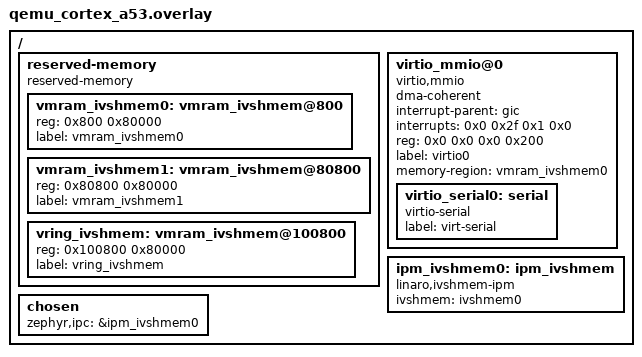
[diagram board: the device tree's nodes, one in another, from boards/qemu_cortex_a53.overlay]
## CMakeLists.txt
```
# SPDX-License-Identifier: Apache-2.0

cmake_minimum_required(VERSION 3.13.1)

# list(APPEND QEMU_EXTRA_FLAGS -S)
# list(APPEND QEMU_EXTRA_FLAGS -s)

find_package(Zephyr REQUIRED HINTS $ENV{ZEPHYR_BASE})
project(hello_world)
zephyr_compile_definitions(METAL_MAX_DEVICE_REGIONS=2)

target_sources(app PRIVATE src/main.c src/virtio_mmio_ivshmem.c)
```

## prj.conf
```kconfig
CONFIG_VIRTIO=y
CONFIG_VIRTIO_MMIO=y
CONFIG_VIRTIO_MMIO_USE_IVSHMEM=y
CONFIG_COMPILER_OPT=" -DHVL_VIRTIO"
CONFIG_VIRTIO_SERIAL=y
CONFIG_UART_INTERRUPT_DRIVEN=n

CONFIG_BOOT_BANNER=n
CONFIG_EARLY_CONSOLE=n
CONFIG_CONSOLE=n

CONFIG_OPENAMP=y
CONFIG_LIBMETAL=y
# CONFIG_HEAP_MEM_POOL_SIZE=131072
CONFIG_IPM=y
```

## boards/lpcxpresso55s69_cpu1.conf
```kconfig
CONFIG_IPM_MCUX=y
```

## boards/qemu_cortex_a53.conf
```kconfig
# Copyright (c) 2023 Linaro
# SPDX-License-Identifier: Apache-2.0

CONFIG_PCIE_CONTROLLER=y
CONFIG_PCIE_ECAM=y

# Hungry PCI requires at least 256M of virtual space
CONFIG_KERNEL_VM_SIZE=0x80000000

# Hungry PCI requires phys addresses with more than 32 bits
CONFIG_ARM64_VA_BITS_40=y
CONFIG_ARM64_PA_BITS_40=y

# MSI support requires ITS
CONFIG_GIC_V3_ITS=y

# ITS, in turn, requires dynamic memory (9x64 + alignment constrains)
# Additionally, our test also uses malloc
CONFIG_HEAP_MEM_POOL_SIZE=1048576
CONFIG_IPM_IVSHMEM_EVENT_LOOP_PRIO=0

CONFIG_PCIE=y
# required by doorbell
CONFIG_PCIE_MSI=y
CONFIG_PCIE_MSI_X=y
CONFIG_PCIE_MSI_MULTI_VECTOR=y
CONFIG_POLL=y

CONFIG_VIRTUALIZATION=y
CONFIG_IVSHMEM=y
CONFIG_IVSHMEM_DOORBELL=y
```

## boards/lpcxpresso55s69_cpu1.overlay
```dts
/*
 * Copyright (c) 2019 Linaro Limited
 *
 * SPDX-License-Identifier: Apache-2.0
 */

 / {
	chosen {
		zephyr,ipc = &mailbox0;
	};

	/* This is a duplication of sram4, workaround */
	sram4duplicate: memory@20040000 {
		compatible = "mmio-sram";
		reg = <0x20040000 DT_SIZE_K(16)>;
	};

	virtio_mmio@20040000 {
		dma-coherent;
		interrupt-parent = < &nvic >;
		/* use the same interrupt from mailbox peripheral*/
		interrupts = <31 0>;;
		reg = < 20040000 0x200 >;
		compatible = "virtio,mmio";
		status = "okay";
		label = "virtio0";
		memory-region = < &sram4duplicate >;
		virtio_serial0: serial {
			label = "virt-serial";
			compatible = "virtio-serial";
		};
	};
};
```

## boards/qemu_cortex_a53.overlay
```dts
/*
 * Copyright 2023 Linaro.
 *
 * SPDX-License-Identifier: Apache-2.0
 */
#include "pcie_ivshmem.dtsi"

/{
	reserved-memory {
		compatible = "reserved-memory";
		#address-cells = <1>;
		#size-cells = <1>;
		status = "okay";
		ranges;

		vmram_ivshmem0: vmram_ivshmem@800 {
			status = "okay";
			reg = < 0x800 0x80000 >;
			device_type = "memory";
			label = "vmram_ivshmem0";
		};

		vmram_ivshmem1: vmram_ivshmem@80800 {
			status = "okay";
			reg = < 0x80800 0x80000 >;
			device_type = "memory";
			label = "vmram_ivshmem1";
		};

		/* reserve this area for the vrings */
		vring_ivshmem: vmram_ivshmem@100800 {
			status = "okay";
			reg = < 0x100800 0x80000 >;
			device_type = "memory";
			label = "vring_ivshmem";
		};
	};

	virtio_mmio@0 {
		dma-coherent;
		interrupt-parent = < &gic >;
		interrupts = < 0x0 0x2f 0x1 0x0 >;
		reg = < 0x0 0x0 0x0 0x200 >;
		compatible = "virtio,mmio";
		status = "okay";
		label = "virtio0";
		memory-region = < &vmram_ivshmem0 >;
		virtio_serial0: serial {
			label = "virt-serial";
			compatible = "virtio-serial";
		};
	};

	ipm_ivshmem0: ipm_ivshmem {
		compatible = "linaro,ivshmem-ipm";
		ivshmem = <&ivshmem0>;
		status = "okay";
	};

	chosen {
		zephyr,ipc = &ipm_ivshmem0;
	};
};
```

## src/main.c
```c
/*
 * Copyright (c) 2012-2014 Wind River Systems, Inc.
 *
 * SPDX-License-Identifier: Apache-2.0
 */

#include <zephyr/kernel.h>
#include <zephyr/sys/printk.h>
#include <zephyr/init.h>
#include <zephyr/drivers/uart.h>

const struct device *virtio_serial = DEVICE_DT_GET(DT_NODELABEL(virtio_serial0));

/* override the printk output char with our virtio_serial driver: */
int arch_printk_char_out(int c)
{
	if(!device_is_ready(virtio_serial))
		return 0;

	uart_poll_out(virtio_serial, c);
	k_sleep(K_USEC(200));
	return 0;
}

void main(void)
{
	while(1){
		printk("[%d]: Hello World I'm %s sending data over Virtio-MMIO Serial Port\n",
			k_uptime_get_32(),
			CONFIG_BOARD);
	}
}
```

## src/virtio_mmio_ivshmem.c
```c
/*
 * Copyright (c) 2023, Linaro Limited
 *
 * SPDX-License-Identifier: Apache-2.0
 */
#include <stdio.h>
#include <string.h>

#include <zephyr/device.h>
#include <zephyr/drivers/virtualization/ivshmem.h>
#include <zephyr/drivers/ipm.h>
#include <zephyr/sys/printk.h>
#include <zephyr/kernel.h>
#include <zephyr/init.h>

#include <openamp/virtio_mmio.h>

static const struct device *ivshmem_dev =
		DEVICE_DT_GET(DT_NODELABEL(ivshmem0));

static const struct device *ipm_dev =
		DEVICE_DT_GET(DT_CHOSEN(zephyr_ipc));

static void ipm_platform_callback(const struct device *ipmdev,
						void *user_data,
			       		uint32_t id,
						volatile void *data)
{
	ARG_UNUSED(ipmdev);
	ARG_UNUSED(id);
	ARG_UNUSED(data);

	extern void virtio_mmio_hvl_cb_run(void);
	virtio_mmio_hvl_cb_run();
}


void virtio_mmio_hvl_ipi(void)
{
	uint16_t peer_dest_id = ivshmem_get_id(ivshmem_dev) - 1;
	ipm_send(ipm_dev, 0, peer_dest_id, NULL, 0);
}

void virtio_mmio_hvl_wait(uint32_t usec)
{
	k_busy_wait(usec);
}

static int init_ivshmem_backend(void)
{
	ipm_register_callback(ipm_dev, ipm_platform_callback, NULL);
	ipm_set_enabled(ipm_dev, 1);
	return 0;
}

SYS_INIT(init_ivshmem_backend, POST_KERNEL, CONFIG_APPLICATION_INIT_PRIORITY);
```
